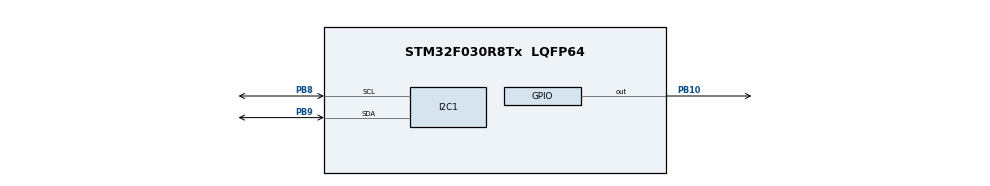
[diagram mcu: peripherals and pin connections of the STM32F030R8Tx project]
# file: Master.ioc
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Mcu.Family=STM32F0
Mcu.Name=STM32F030R8Tx
Mcu.Package=LQFP64
PA13.Mode=Serial_Wire
PA13.Signal=SYS_SWDIO
PA14.Mode=Serial_Wire
PA14.Signal=SYS_SWCLK
PB10.Signal=GPIO_Output
PB8.Mode=I2C
PB8.Signal=I2C1_SCL
PB9.Mode=I2C
PB9.Signal=I2C1_SDA
ProjectManager.HeapSize=0x200
ProjectManager.StackSize=0x400
ProjectManager.TargetToolchain=STM32CubeIDE
board=custom

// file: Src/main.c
 /* USER CODE BEGIN Header */
/**
  ******************************************************************************
  * @file           : main.c
  * @brief          : Main program body
  ******************************************************************************
  * @attention
  *
  * <h2><center>&copy; Copyright (c) 2020 STMicroelectronics.
  * All rights reserved.</center></h2>
  *
  * This software component is licensed by ST under BSD 3-Clause license,
  * the "License"; You may not use this file except in compliance with the
  * License. You may obtain a copy of the License at:
  *                        opensource.org/licenses/BSD-3-Clause
  *
  ******************************************************************************
  */
/* USER CODE END Header */

#include "main.h"

/* USER CODE BEGIN Includes */
#include "stdio.h"
#include "stdlib.h"
#include <stdbool.h>
/* USER CODE END Includes */

I2C_HandleTypeDef hi2c1;

void SystemClock_Config(void);
static void MX_GPIO_Init(void);
static void MX_I2C1_Init(void);

int main(void)
{

  /* MCU Configuration--------------------------------------------------------*/

  /* Reset of all peripherals, Initializes the Flash interface and the Systick. */
  HAL_Init();

  /* Configure the system clock */
  SystemClock_Config();

  /* Initialize all configured peripherals */
  MX_GPIO_Init();
  MX_I2C1_Init();
  /* USER CODE BEGIN 2 */
  GPIOB -> ODR &= ~GPIO_PIN_10;

  //Unit select register: 3B(4th bit)

		//50 = write address,    51= read address

//Getting the units binary

   //uint8_t* units = (uint8_t *) 0x3B;

//    HAL_I2C_Master_Transmit(&hi2c1, 0x50, (uint8_t *) 0x34, 1, HAL_MAX_DELAY);
//    HAL_I2C_Master_Receive(&hi2c1, 0x50, pdata1, 1, HAL_MAX_DELAY);

      uint8_t slaveAddress = 0x50; // 0x29
	HAL_I2C_IsDeviceReady(&hi2c1,slaveAddress,1, HAL_MAX_DELAY);

		while(HAL_I2C_IsDeviceReady(&hi2c1,slaveAddress,1, HAL_MAX_DELAY!=HAL_OK)) //True= Found Device       False= Device Not Found
		{
			if(HAL_I2C_IsDeviceReady(&hi2c1,slaveAddress,1, HAL_MAX_DELAY)==HAL_OK) break;
		}

//self test reg is 0x36 , calibration reg is 0x35
	  uint8_t	calibarationReg = 0x35;
	  uint8_t	calibrationData=0;
	  uint8_t *pCalibration;
	  pCalibration=&calibrationData;

/*
 * Operating mode
 * xxxx0000 = Config Mode
 * xxxx0111 = All 3 on
 */
		  uint8_t	OPRreg = 0x3D;
		  uint8_t	OPRData=0;
		  uint8_t *pOPR;
		  pOPR=&OPRData;

/*
 * Units
 * 5th bit is for temp sensor. 0 is for Celsius and 1 is for Fahrenheit
 */
		  uint8_t	unitsReg = 0x3B;
		  uint8_t	UnitData=0;
		  uint8_t *pUnits;
		  pUnits=&UnitData;
/*
 * Power
 */
		  uint8_t	powerReg = 0x3E;
		  uint8_t	powerData=0;
		  uint8_t *pPower;
		  pPower=&powerData;

/*
 * Temperature
 */
		  uint8_t tempdata = 0;
		  uint8_t tempReg = 0x34;
		  uint8_t *ptemp;
		  ptemp=&tempdata;
/*
 * Temperature Source
 * The temperature can either come from the gyroscope (xxxxxx01) or the accelerameter(xxxxxx00)
 */

	      uint8_t sourceReg = 0x40;
	      uint8_t sourceData = 0;
		  uint8_t *pSource;
		  pSource=&sourceData;

//TURN ON POWER
		HAL_I2C_Mem_Read(&hi2c1,slaveAddress,powerReg,1,pPower,1,50);
		HAL_Delay(100);
		//Bit manipulation to change the data the normal mode (goal is xxxxxx00)
		powerData&=0xFC; //11111100
		HAL_I2C_Mem_Write(&hi2c1,slaveAddress,powerReg,1,pPower,1,50);
		HAL_Delay(100);

//TURN ON ALL SENSORS
		HAL_I2C_Mem_Read(&hi2c1,slaveAddress,OPRreg,1,pOPR,1,50); //Checks what mode the sensor is in
		HAL_Delay(100);
		//Bit manipulation to change the data into the mode which allows all 3 sensors on (goal is xxxx0111)
		OPRData&=0xF7;//11110111
		OPRData|=0x07; //00000111
		HAL_I2C_Mem_Write(&hi2c1,slaveAddress,OPRreg,1,pOPR,1,50);//Tells the sensors to turn on and collect data by changing mode
		HAL_Delay(100);

//TURN ON CHANGE TEMP READER TO ACCLEROMETER
		HAL_I2C_Mem_Read(&hi2c1,slaveAddress,sourceReg,1,pSource,1,50);
		HAL_Delay(100);
		//Bit manipulation (goal is xxxxxx00)
		sourceData&=0xFC; //11111100
		HAL_I2C_Mem_Write(&hi2c1,slaveAddress,sourceReg,1,pSource,1,50);
		HAL_Delay(100);

//PUT UNITS INTO CELCIUS
		HAL_I2C_Mem_Read(&hi2c1,slaveAddress,unitsReg,1,pUnits,1,50); //Checks to see the units
		HAL_Delay(100);
		//Bit manipulation to change the data into celcius while preserving data that is unrelated (goal is xxx0xxxx)
		UnitData&=0xEF;//11101111
		HAL_I2C_Mem_Write(&hi2c1,slaveAddress,unitsReg,1,pUnits,1,50);
		HAL_Delay(100);

//GET TEMP
		HAL_I2C_Mem_Read(&hi2c1,slaveAddress,tempReg,1,ptemp,1,50);
		HAL_Delay(100);

      HAL_Delay(100);

  /* USER CODE END 2 */

  /* Infinite loop */
  while (1)
  {

  }
}

void SystemClock_Config(void)
{
  RCC_OscInitTypeDef RCC_OscInitStruct = {0};
  RCC_ClkInitTypeDef RCC_ClkInitStruct = {0};
  RCC_PeriphCLKInitTypeDef PeriphClkInit = {0};

  /** Initializes the CPU, AHB and APB busses clocks
  */
  RCC_OscInitStruct.OscillatorType = RCC_OSCILLATORTYPE_HSI;
  RCC_OscInitStruct.HSIState = RCC_HSI_ON;
  RCC_OscInitStruct.HSICalibrationValue = RCC_HSICALIBRATION_DEFAULT;
  RCC_OscInitStruct.PLL.PLLState = RCC_PLL_NONE;
  if (HAL_RCC_OscConfig(&RCC_OscInitStruct) != HAL_OK)
  {
    Error_Handler();
  }
  /** Initializes the CPU, AHB and APB busses clocks
  */
  RCC_ClkInitStruct.ClockType = RCC_CLOCKTYPE_HCLK|RCC_CLOCKTYPE_SYSCLK
                              |RCC_CLOCKTYPE_PCLK1;
  RCC_ClkInitStruct.SYSCLKSource = RCC_SYSCLKSOURCE_HSI;
  RCC_ClkInitStruct.AHBCLKDivider = RCC_SYSCLK_DIV1;
  RCC_ClkInitStruct.APB1CLKDivider = RCC_HCLK_DIV1;

  if (HAL_RCC_ClockConfig(&RCC_ClkInitStruct, FLASH_LATENCY_0) != HAL_OK)
  {
    Error_Handler();
  }
  PeriphClkInit.PeriphClockSelection = RCC_PERIPHCLK_I2C1;
  PeriphClkInit.I2c1ClockSelection = RCC_I2C1CLKSOURCE_HSI;
  if (HAL_RCCEx_PeriphCLKConfig(&PeriphClkInit) != HAL_OK)
  {
    Error_Handler();
  }
}

static void MX_I2C1_Init(void)
{

  hi2c1.Instance = I2C1;
  hi2c1.Init.Timing = 0x2000090E;
  hi2c1.Init.OwnAddress1 = 0;
  hi2c1.Init.AddressingMode = I2C_ADDRESSINGMODE_7BIT;
  hi2c1.Init.DualAddressMode = I2C_DUALADDRESS_DISABLE;
  hi2c1.Init.OwnAddress2 = 0;
  hi2c1.Init.OwnAddress2Masks = I2C_OA2_NOMASK;
  hi2c1.Init.GeneralCallMode = I2C_GENERALCALL_DISABLE;
  hi2c1.Init.NoStretchMode = I2C_NOSTRETCH_DISABLE;
  if (HAL_I2C_Init(&hi2c1) != HAL_OK)
  {
    Error_Handler();
  }
  /** Configure Analogue filter
  */
  if (HAL_I2CEx_ConfigAnalogFilter(&hi2c1, I2C_ANALOGFILTER_ENABLE) != HAL_OK)
  {
    Error_Handler();
  }
  /** Configure Digital filter
  */
  if (HAL_I2CEx_ConfigDigitalFilter(&hi2c1, 0) != HAL_OK)
  {
    Error_Handler();
  }

}

static void MX_GPIO_Init(void)
{
  GPIO_InitTypeDef GPIO_InitStruct = {0};

  /* GPIO Ports Clock Enable */
  __HAL_RCC_GPIOB_CLK_ENABLE();
  __HAL_RCC_GPIOA_CLK_ENABLE();

  /*Configure GPIO pin Output Level */
  HAL_GPIO_WritePin(GPIOB, GPIO_PIN_10, GPIO_PIN_RESET);

  /*Configure GPIO pin : PB10 */
  GPIO_InitStruct.Pin = GPIO_PIN_10;
  GPIO_InitStruct.Mode = GPIO_MODE_OUTPUT_PP;
  GPIO_InitStruct.Pull = GPIO_NOPULL;
  GPIO_InitStruct.Speed = GPIO_SPEED_FREQ_LOW;
  HAL_GPIO_Init(GPIOB, &GPIO_InitStruct);

}

void Error_Handler(void)
{
}

/************************ (C) COPYRIGHT STMicroelectronics *****END OF FILE****/
